VERSION ""

NS_ :

BS_:

BU_: ECM

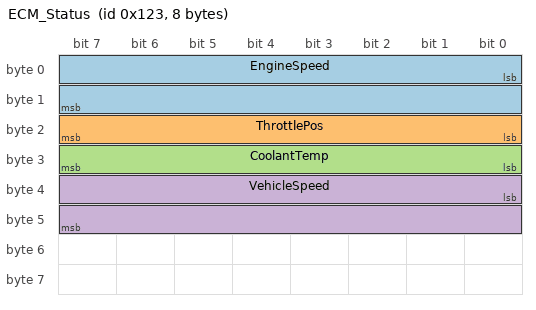
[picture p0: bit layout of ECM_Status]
BO_ 291 ECM_Status: 8 ECM
 SG_ EngineSpeed : 0|16@1+ (0.25,0) [0|16383.75] "rpm" ECM
 SG_ ThrottlePos : 16|8@1+ (0.3921568627,0) [0|100] "%" ECM
 SG_ CoolantTemp : 24|8@1+ (1,-40) [-40|215] "degC" ECM
 SG_ VehicleSpeed : 32|16@1+ (0.01,0) [0|655.35] "km/h" ECM

CM_ BO_ 291 "Przykladowa wiadomosc demonstracyjna (fikcyjna) - nie jest to prawdziwa ramka.";
CM_ SG_ 291 EngineSpeed "Obroty silnika (demo).";
CM_ SG_ 291 VehicleSpeed "Predkosc pojazdu (demo).";
